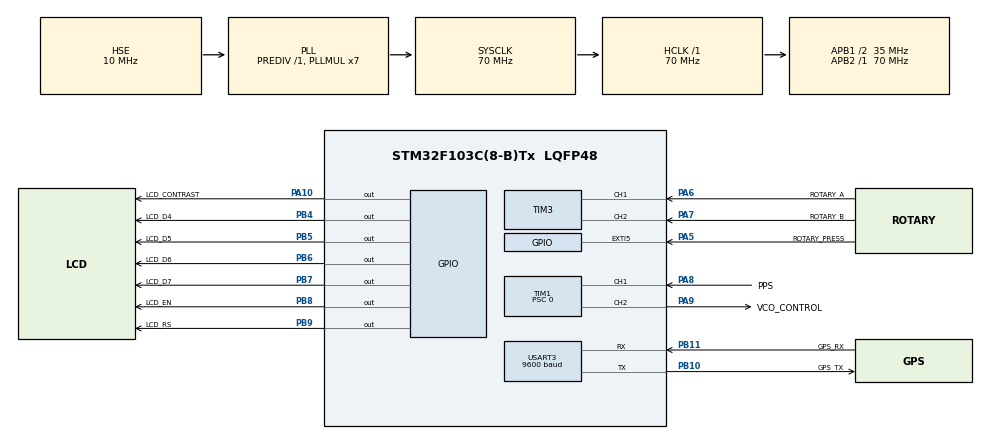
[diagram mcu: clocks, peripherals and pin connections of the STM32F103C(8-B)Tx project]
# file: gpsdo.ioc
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Mcu.Family=STM32F1
Mcu.Name=STM32F103C(8-B)Tx
Mcu.Package=LQFP48
NVIC.EXTI9_5_IRQn=true\:0\:0\:false\:false\:true\:true\:true\:true
NVIC.PriorityGroup=NVIC_PRIORITYGROUP_4
NVIC.TIM1_CC_IRQn=true\:0\:0\:false\:false\:true\:true\:true\:true
NVIC.TIM1_UP_IRQn=true\:0\:0\:false\:false\:true\:true\:true\:true
NVIC.TIM2_IRQn=true\:0\:0\:false\:false\:true\:true\:true\:true
PA10.GPIO_Label=LCD_CONTRAST
PA10.Signal=GPIO_Output
PA13.Mode=Serial_Wire
PA13.Signal=SYS_JTMS-SWDIO
PA14.Mode=Serial_Wire
PA14.Signal=SYS_JTCK-SWCLK
PA5.GPIO_Label=ROTARY_PRESS
PA5.GPIO_ModeDefaultEXTI=GPIO_MODE_IT_RISING_FALLING
PA5.GPIO_PuPd=GPIO_PULLUP
PA5.Signal=GPXTI5
PA6.GPIO_Label=ROTARY_A
PA6.GPIO_PuPd=GPIO_PULLUP
PA6.Signal=S_TIM3_CH1
PA7.GPIO_Label=ROTARY_B
PA7.GPIO_PuPd=GPIO_PULLUP
PA7.Signal=S_TIM3_CH2
PA8.GPIO_Label=PPS
PA8.GPIO_PuPd=GPIO_PULLDOWN
PA8.Signal=S_TIM1_CH1
PA9.GPIO_Label=VCO_CONTROL
PA9.Signal=S_TIM1_CH2
PB10.GPIO_Label=GPS_TX
PB10.Mode=Asynchronous
PB10.Signal=USART3_TX
PB11.GPIO_Label=GPS_RX
PB11.Mode=Asynchronous
PB11.Signal=USART3_RX
PB4.GPIO_Label=LCD_D4
PB4.Signal=GPIO_Output
PB5.GPIO_Label=LCD_D5
PB5.Signal=GPIO_Output
PB6.GPIO_Label=LCD_D6
PB6.Signal=GPIO_Output
PB7.GPIO_Label=LCD_D7
PB7.Signal=GPIO_Output
PB8.GPIO_Label=LCD_EN
PB8.Signal=GPIO_Output
PB9.GPIO_Label=LCD_RS
PB9.Signal=GPIO_Output
PC14-OSC32_IN.Mode=LSE-External-Oscillator
PC14-OSC32_IN.Signal=RCC_OSC32_IN
PC15-OSC32_OUT.Mode=LSE-External-Oscillator
PC15-OSC32_OUT.Signal=RCC_OSC32_OUT
PD0-OSC_IN.Mode=HSE-External-Clock-Source
PD0-OSC_IN.Signal=RCC_OSC_IN
PD1-OSC_OUT.Mode=HSE-External-Clock-Source
PD1-OSC_OUT.Signal=RCC_OSC_OUT
ProjectManager.HeapSize=0x200
ProjectManager.StackSize=0x400
ProjectManager.TargetToolchain=CMake
RCC.AHBFreq_Value=70000000
RCC.APB1CLKDivider=RCC_HCLK_DIV2
RCC.APB1Freq_Value=35000000
RCC.APB1TimFreq_Value=70000000
RCC.APB2Freq_Value=70000000
RCC.APB2TimFreq_Value=70000000
RCC.HCLKFreq_Value=70000000
RCC.HSE_Timout=1000
RCC.HSE_VALUE=10000000
RCC.PLLMUL=RCC_PLL_MUL7
RCC.PLLSourceVirtual=RCC_PLLSOURCE_HSE
RCC.SYSCLKFreq_VALUE=70000000
RCC.SYSCLKSource=RCC_SYSCLKSOURCE_PLLCLK
RCC.USBFreq_Value=70000000
SH.S_TIM1_CH1.0=TIM1_CH1,Input_Capture1_from_TI1
SH.S_TIM1_CH2.0=TIM1_CH2,PWM Generation2 CH2
SH.S_TIM3_CH1.0=TIM3_CH1,Encoder_Interface
SH.S_TIM3_CH2.0=TIM3_CH2,Encoder_Interface
TIM1.AutoReloadPreload=TIM_AUTORELOAD_PRELOAD_DISABLE
TIM1.AutomaticOutput=TIM_AUTOMATICOUTPUT_DISABLE
TIM1.BreakState=TIM_BREAK_DISABLE
TIM1.Channel-Input_Capture1_from_TI1=TIM_CHANNEL_1
TIM1.Channel-PWM\ Generation2\ CH2=TIM_CHANNEL_2
TIM1.ClockDivision=TIM_CLOCKDIVISION_DIV1
TIM1.CounterMode=TIM_COUNTERMODE_UP
TIM1.ICFilter_CH1=0
TIM1.OCFastMode_PWM-PWM\ Generation2\ CH2=TIM_OCFAST_ENABLE
TIM1.Period=65535
TIM1.Prescaler=0
TIM1.Pulse-PWM\ Generation2\ CH2=0
TIM2.Period=10000
TIM2.Prescaler=7000
TIM3.IC1Filter=15
TIM3.IC2Filter=15
USART3.BaudRate=9600
USART3.VirtualMode=VM_ASYNC
VP_TIM1_VS_ClockSourceINT.Mode=Internal
VP_TIM2_VS_ClockSourceINT.Mode=Internal
board=custom

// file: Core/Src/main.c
/* USER CODE BEGIN Header */
/**
  ******************************************************************************
  * @file           : main.c
  * @brief          : Main program body
  ******************************************************************************
  * @attention
  *
  * Copyright (c) 2024 STMicroelectronics.
  * All rights reserved.
  *
  * This software is licensed under terms that can be found in the LICENSE file
  * in the root directory of this software component.
  * If no LICENSE file comes with this software, it is provided AS-IS.
  *
  ******************************************************************************
  */
/* USER CODE END Header */
#include "main.h"
#include "tim.h"
#include "usart.h"
#include "gpio.h"

/* USER CODE BEGIN Includes */
#include "LCD.h"
/* USER CODE END Includes */

void SystemClock_Config(void);
/* USER CODE BEGIN PFP */
void gpsdo(void);
/* USER CODE END PFP */

int main(void)
{

  /* MCU Configuration--------------------------------------------------------*/

  /* Reset of all peripherals, Initializes the Flash interface and the Systick. */
  HAL_Init();

  /* Configure the system clock */
  SystemClock_Config();

  /* Initialize all configured peripherals */
  MX_GPIO_Init();
  MX_USART3_UART_Init();
  MX_TIM1_Init();
  MX_TIM3_Init();
  MX_TIM2_Init();
  /* USER CODE BEGIN 2 */
  gpsdo();
  /* USER CODE END 2 */

  /* Infinite loop */
  /* USER CODE BEGIN WHILE */
  while (1)
  {

      /*uint8_t buffer[512];
    if(HAL_UART_Receive(&huart3, buffer, 1, 1000) == HAL_OK)
    {
      CDC_Transmit_FS(buffer, 1);
    }*/

    /* USER CODE END WHILE */

  }
}

void SystemClock_Config(void)
{
  RCC_OscInitTypeDef RCC_OscInitStruct = {0};
  RCC_ClkInitTypeDef RCC_ClkInitStruct = {0};

  /** Initializes the RCC Oscillators according to the specified parameters
  * in the RCC_OscInitTypeDef structure.
  */
  RCC_OscInitStruct.OscillatorType = RCC_OSCILLATORTYPE_HSE;
  RCC_OscInitStruct.HSEState = RCC_HSE_BYPASS;
  RCC_OscInitStruct.HSEPredivValue = RCC_HSE_PREDIV_DIV1;
  RCC_OscInitStruct.HSIState = RCC_HSI_ON;
  RCC_OscInitStruct.PLL.PLLState = RCC_PLL_ON;
  RCC_OscInitStruct.PLL.PLLSource = RCC_PLLSOURCE_HSE;
  RCC_OscInitStruct.PLL.PLLMUL = RCC_PLL_MUL7;
  if (HAL_RCC_OscConfig(&RCC_OscInitStruct) != HAL_OK)
  {
    Error_Handler();
  }

  /** Initializes the CPU, AHB and APB buses clocks
  */
  RCC_ClkInitStruct.ClockType = RCC_CLOCKTYPE_HCLK|RCC_CLOCKTYPE_SYSCLK
                              |RCC_CLOCKTYPE_PCLK1|RCC_CLOCKTYPE_PCLK2;
  RCC_ClkInitStruct.SYSCLKSource = RCC_SYSCLKSOURCE_PLLCLK;
  RCC_ClkInitStruct.AHBCLKDivider = RCC_SYSCLK_DIV1;
  RCC_ClkInitStruct.APB1CLKDivider = RCC_HCLK_DIV2;
  RCC_ClkInitStruct.APB2CLKDivider = RCC_HCLK_DIV1;

  if (HAL_RCC_ClockConfig(&RCC_ClkInitStruct, FLASH_LATENCY_2) != HAL_OK)
  {
    Error_Handler();
  }
}

void Error_Handler(void)
{
  __disable_irq();
  while (1)
  {
  }
}
